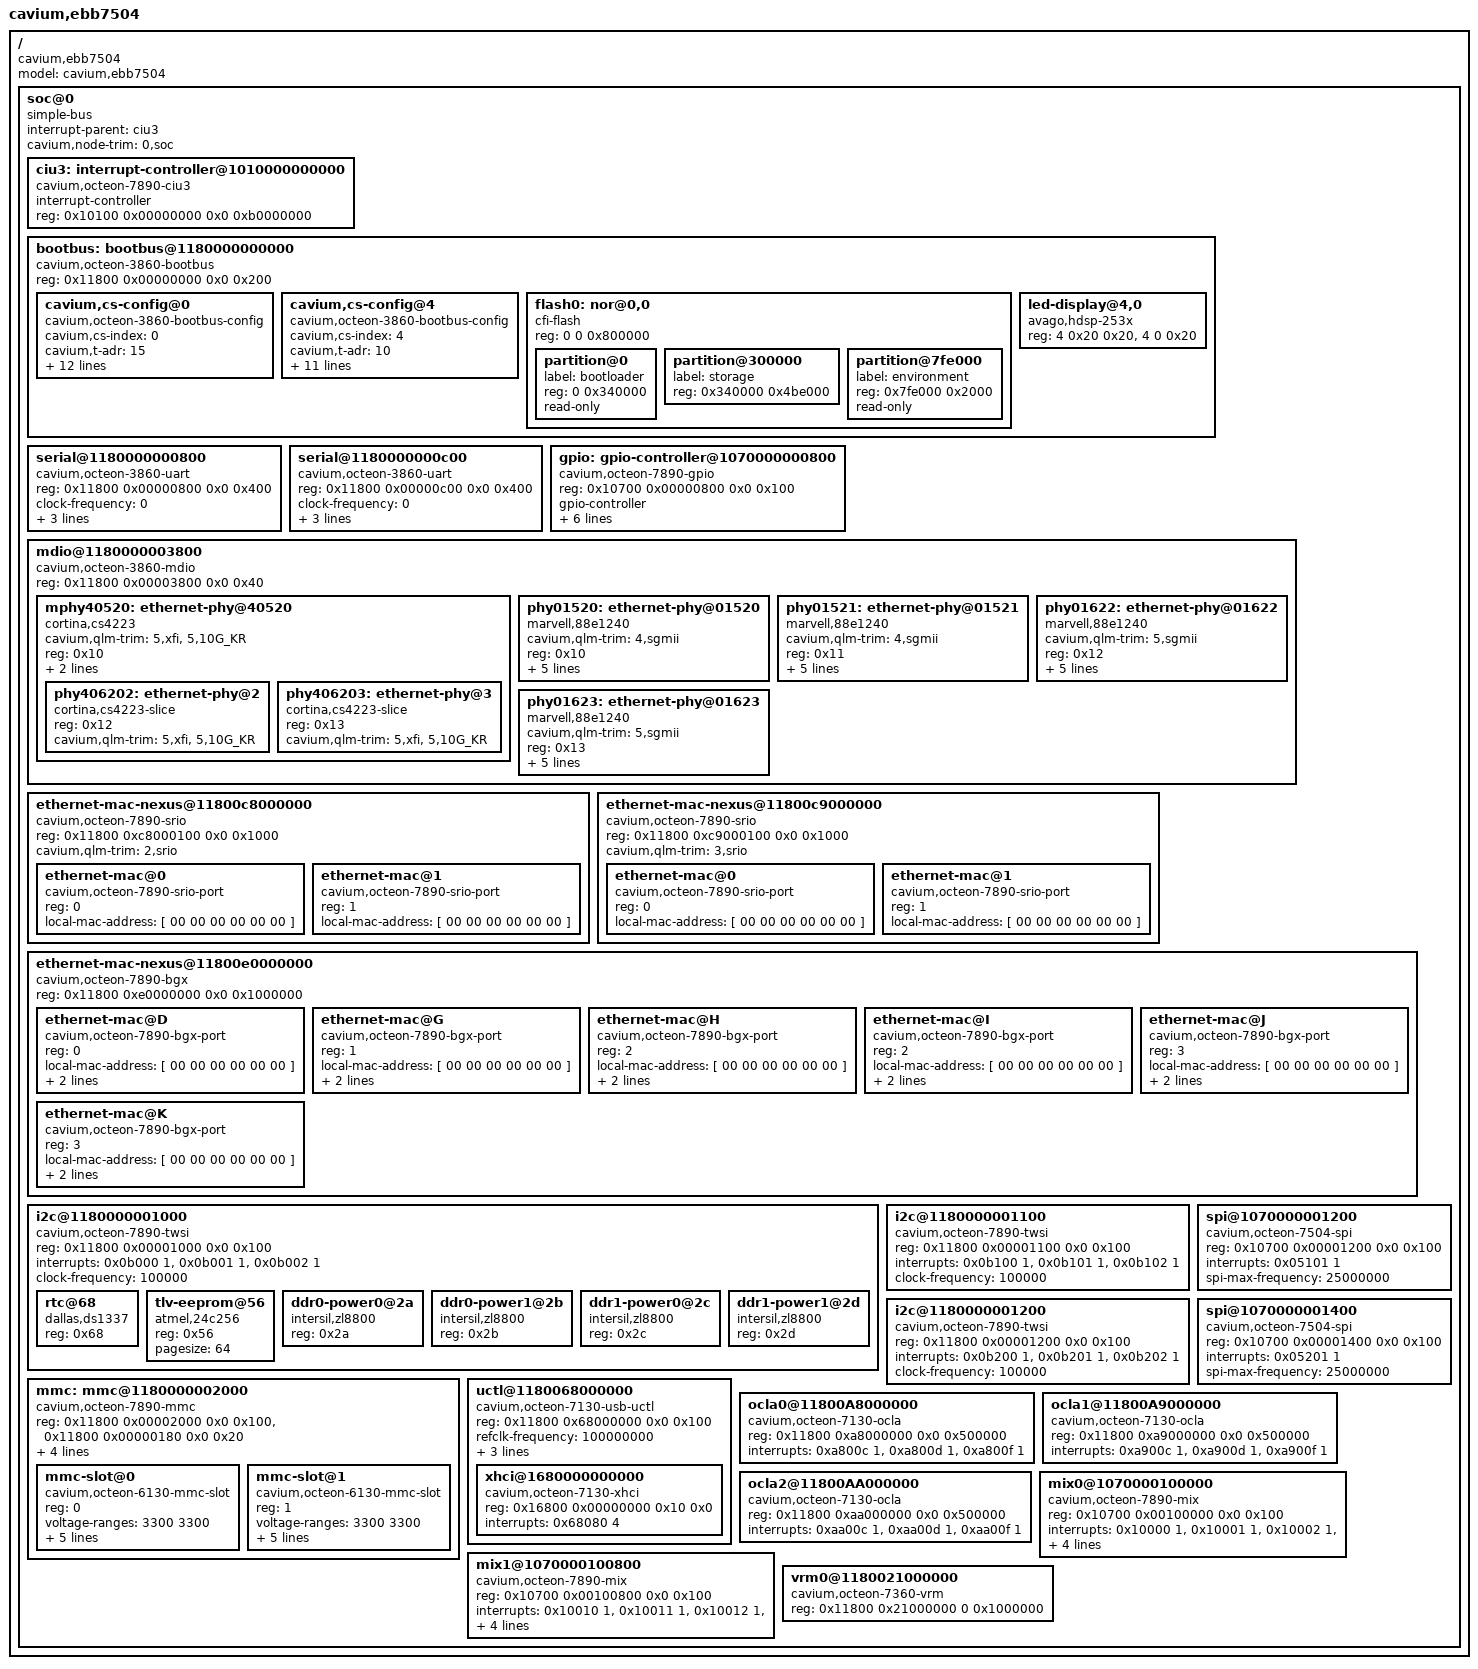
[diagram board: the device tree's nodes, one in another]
/dts-v1/;
/*
 * Cavium Inc. EVB CN7500
 */
/ {
	model = "cavium,ebb7504";
	compatible = "cavium,ebb7504";
	#address-cells = <2>;
	#size-cells = <2>;

	soc@0 {
		interrupt-parent = <&ciu3>;
		compatible = "simple-bus";
		#address-cells = <2>;
		#size-cells = <2>;
		ranges; /* Direct mapping */
		cavium,node-trim = "0,soc";

		ciu3: interrupt-controller@1010000000000 {
			compatible = "cavium,octeon-7890-ciu3";
			interrupt-controller;
			/* Interrupts are specified by two parts:
			 * 1) Source number (20 significant bits)
			 * 2) Trigger type: (4 == level, 1 == edge)
			 */
			#address-cells = <0>;
			#interrupt-cells = <2>;
			reg = <0x10100 0x00000000 0x0 0xb0000000>;
		};

		bootbus: bootbus@1180000000000 {
			compatible = "cavium,octeon-3860-bootbus";
			reg = <0x11800 0x00000000 0x0 0x200>;
			/* The chip select number and offset */
			#address-cells = <2>;
			/* The size of the chip select region */
			#size-cells = <1>;
			ranges = <0 0  0       0x1f400000  0xc00000>,
				 <1 0  0x10000 0x10000000  0>,
				 <2 0  0x10000 0x20000000  0>,
				 <3 0  0x10000 0x30000000  0>,
				 <4 0  0       0x1d020000  0x10000>,
				 <5 0  0x10000 0x50000000  0>,
				 <6 0  0x10000 0x60000000  0>,
				 <7 0  0x10000 0x70000000  0>;

			cavium,cs-config@0 {
				compatible = "cavium,octeon-3860-bootbus-config";
				cavium,cs-index = <0>;
				cavium,t-adr  = <15>;
				cavium,t-ce   = <55>;
				cavium,t-oe   = <55>;
				cavium,t-we   = <40>;
				cavium,t-rd-hld = <30>;
				cavium,t-wr-hld = <40>;
				cavium,t-pause  = <0>;
				cavium,t-wait   = <65>;
				cavium,t-page   = <35>;
				cavium,t-rd-dly = <0>;

				cavium,page-mode = <1>;
				cavium,pages     = <8>;
				cavium,bus-width = <8>;
			};
			cavium,cs-config@4 {
				compatible = "cavium,octeon-3860-bootbus-config";
				cavium,cs-index = <4>;
				cavium,t-adr  = <10>;
				cavium,t-ce   = <10>;
				cavium,t-oe   = <160>;
				cavium,t-we   = <100>;
				cavium,t-rd-hld = <10>;
				cavium,t-wr-hld = <0>;
				cavium,t-pause  = <50>;
				cavium,t-wait   = <60>;
				cavium,t-page   = <10>;
				cavium,t-rd-dly = <10>;

				cavium,pages     = <0>;
				cavium,bus-width = <8>;
			};
			flash0: nor@0,0 {
				compatible = "cfi-flash";
				reg = <0 0 0x800000>;
				#address-cells = <1>;
				#size-cells = <1>;

				partition@0 {
					label = "bootloader";
					reg = <0 0x340000>;
					read-only;
				};
				partition@300000 {
					label = "storage";
					reg = <0x340000 0x4be000>;
				};
				partition@7fe000 {
					label = "environment";
					reg = <0x7fe000 0x2000>;
					read-only;
				};
			};
			led-display@4,0 {
				compatible = "avago,hdsp-253x";
				reg = <4 0x20 0x20>, <4 0 0x20>;
			};
		};

		serial@1180000000800 {
			compatible = "cavium,octeon-3860-uart","ns16550";
			reg = <0x11800 0x00000800 0x0 0x400>;
			clock-frequency = <0>;
			current-speed = <115200>;
			reg-shift = <3>;
			interrupts = <0x08000 4>;
		};

		serial@1180000000c00 {
			compatible = "cavium,octeon-3860-uart","ns16550";
			reg = <0x11800 0x00000c00 0x0 0x400>;
			clock-frequency = <0>;
			current-speed = <115200>;
			reg-shift = <3>;
			interrupts = <0x08040 4>;
		};

		gpio: gpio-controller@1070000000800 {
			#gpio-cells = <2>;
			compatible = "cavium,octeon-7890-gpio";
			reg = <0x10700 0x00000800 0x0 0x100>;
			gpio-controller;
			/* Interrupts are specified by two parts:
			 * 1) GPIO pin number (0..15)
			 * 2) Triggering (1 - edge rising
			 *		  2 - edge falling
			 *		  4 - level active high
			 *		  8 - level active low)
			 */
			interrupt-controller;
			#interrupt-cells = <2>;
			/* The GPIO pins connect to 16 consecutive CUI bits */
			interrupts = <0x03000 4>, <0x03001 4>,
				     <0x03002 4>, <0x03003 4>,
				     <0x03004 4>, <0x03005 4>,
				     <0x03006 4>, <0x03007 4>,
				     <0x03008 4>, <0x03009 4>,
				     <0x0300a 4>, <0x0300b 4>,
				     <0x0300c 4>, <0x0300d 4>,
				     <0x0300e 4>, <0x0300f 4>;
		};

		/* SMI_0 -- The only bus connected on Rev 1 boards */
		mdio@1180000003800 {
			compatible = "cavium,octeon-3860-mdio";
			#address-cells = <1>;
			#size-cells = <0>;
			reg = <0x11800 0x00003800 0x0 0x40>;

			/**
			 * The phy names are broken down as follows:
			 * (m)phyxxyzzs
			 * where:
			 *	xx = 01 for SGMII, 10 for DXAUI, 20 for RXAUI
			 *	     and 40 for XFI/LXAUI
			 *	y = QLM/DLM number
			 *	zz = PHY address (decimal)
			 *	s = sub-phy number in the case of the Cortina
			 *	    PHY
			 * a mphy is a nexus phy that contains one or more
			 * sub-phys, for example the Cortina CS4223.
			 */

			/* DLM 4 */
			mphy40520: ethernet-phy@40520 {
				compatible = "cortina,cs4223", "ethernet-phy-nexus";
				cavium,qlm-trim = "5,xfi","5,10G_KR";
				reg = <0x10>;
				#address-cells = <1>;
				#size-cells = <0>;
				interrupt-parent = <&gpio>;
				interrupts = <5 8>;
				/* The Cortina CS4223 can be used either as
				 * XFI or 10G_KR.  In XFI, four separate ports
				 * are supported even though it's only a single
				 * PHY device.
				 */
				phy406202: ethernet-phy@2 {
					compatible = "cortina,cs4223-slice";
					reg = <0x12>;
					cavium,qlm-trim = "5,xfi","5,10G_KR";
				};
				phy406203: ethernet-phy@3 {
					compatible = "cortina,cs4223-slice";
					reg = <0x13>;
					cavium,qlm-trim = "5,xfi","5,10G_KR";
				};
			};
			phy01520: ethernet-phy@01520 {
				cavium,qlm-trim = "4,sgmii";
				reg = <0x10>;
				compatible = "marvell,88e1240", "ethernet-phy-ieee802.3-c22";
				interrupt-parent = <&gpio>;
				interrupts = <5 8>;

				marvell,reg-init = <3 0x10 0 0x8665>,
						   <3 0x11 0 0x00aa>,
						   <3 0x12 0 0x4105>,
						   <3 0x13 0 0x8a08>;
			};
			phy01521: ethernet-phy@01521 {
				cavium,qlm-trim = "4,sgmii";
				reg = <0x11>;
				compatible = "marvell,88e1240", "ethernet-phy-ieee802.3-c22";
				interrupt-parent = <&gpio>;
				interrupts = <5 8>; /* Pin 11, active low */

				marvell,reg-init = <3 0x10 0 0x8665>,
						   <3 0x11 0 0x00aa>,
						   <3 0x12 0 0x4105>,
						   <3 0x13 0 0x8a08>;
			};
			/* DLM 5 */
			phy01622: ethernet-phy@01622 {
				cavium,qlm-trim = "5,sgmii";
				reg = <0x12>;
				compatible = "marvell,88e1240", "ethernet-phy-ieee802.3-c22";
				interrupt-parent = <&gpio>;
				interrupts = <5 8>; /* Pin 11, active low */

				marvell,reg-init = <3 0x10 0 0x8665>,
						   <3 0x11 0 0x00aa>,
						   <3 0x12 0 0x4105>,
						   <3 0x13 0 0x8a08>;
			};
			phy01623: ethernet-phy@01623 {
				cavium,qlm-trim = "5,sgmii";
				reg = <0x13>;
				compatible = "marvell,88e1240", "ethernet-phy-ieee802.3-c22";
				interrupt-parent = <&gpio>;
				interrupts = <5 8>; /* Pin 11, active low */

				marvell,reg-init = <3 0x10 0 0x8665>,
						   <3 0x11 0 0x00aa>,
						   <3 0x12 0 0x4105>,
						   <3 0x13 0 0x8a08>;
			};
		};

		/* SRIO 0*/
		ethernet-mac-nexus@11800c8000000 {
			compatible = "cavium,octeon-7890-srio";
			reg = <0x11800 0xc8000100 0x0 0x1000>;
			#address-cells = <1>;
			#size-cells = <0>;
			cavium,qlm-trim = "2,srio";

			/* Port 0 */
			ethernet-mac@0 {
				compatible = "cavium,octeon-7890-srio-port";
				reg = <0>;
				local-mac-address = [ 00 00 00 00 00 00 ];
			};
			/* Port 1 */
			ethernet-mac@1 {
				compatible = "cavium,octeon-7890-srio-port";
				reg = <1>;
				local-mac-address = [ 00 00 00 00 00 00 ];
			};
		};

		/* SRIO 1*/
		ethernet-mac-nexus@11800c9000000 {
			compatible = "cavium,octeon-7890-srio";
			reg = <0x11800 0xc9000100 0x0 0x1000>;
			#address-cells = <1>;
			#size-cells = <0>;
			cavium,qlm-trim = "3,srio";

			/* Port 0 */
			ethernet-mac@0 {
				compatible = "cavium,octeon-7890-srio-port";
				reg = <0>;
				local-mac-address = [ 00 00 00 00 00 00 ];
			};
			/* Port 1 */
			ethernet-mac@1 {
				compatible = "cavium,octeon-7890-srio-port";
				reg = <1>;
				local-mac-address = [ 00 00 00 00 00 00 ];
			};
		};

		/* BGX definitions here must match sim_board.c settings. */
		/* BGX 0*/
		ethernet-mac-nexus@11800e0000000 {
			compatible = "cavium,octeon-7890-bgx";
			reg = <0x11800 0xe0000000 0x0 0x1000000>;
			#address-cells = <1>;
			#size-cells = <0>;

			/* SerDes 0, may differ from PCS Lane/LMAC */
			ethernet-mac@D {
				compatible = "cavium,octeon-7890-bgx-port";
				reg = <0>;
				local-mac-address = [ 00 00 00 00 00 00 ];
				phy-handle = <&phy01520>;
				cavium,qlm-trim = "4,sgmii";
			};
			/* SerDes 1, may differ from PCS Lane/LMAC */
			ethernet-mac@G {
				compatible = "cavium,octeon-7890-bgx-port";
				reg = <1>;
				local-mac-address = [ 00 00 00 00 00 00 ];
				phy-handle = <&phy01521>;
				cavium,qlm-trim = "4,sgmii";
			};
			/* SerDes 2 (XFI/10G_KR) */
			ethernet-mac@H {
				compatible = "cavium,octeon-7890-bgx-port";
				reg = <2>;
				local-mac-address = [ 00 00 00 00 00 00 ];
				phy-handle = <&phy406202>;
				cavium,qlm-trim = "5,xfi","5,10G_KR";
			};
			/* SerDes 2, may differ from PCS Lane/LMAC */
			ethernet-mac@I {
				compatible = "cavium,octeon-7890-bgx-port";
				reg = <2>;
				local-mac-address = [ 00 00 00 00 00 00 ];
				phy-handle = <&phy01622>;
				cavium,qlm-trim = "5,sgmii";
			};
			/* SerDes 3 (XFI/10G_KR) */
			ethernet-mac@J {
				compatible = "cavium,octeon-7890-bgx-port";
				reg = <3>;
				local-mac-address = [ 00 00 00 00 00 00 ];
				phy-handle = <&phy406203>;
				cavium,qlm-trim = "5,xfi","5,10G_KR";
			};
			/* SerDes 3, may differ from PCS Lane/LMAC */
			ethernet-mac@K {
				compatible = "cavium,octeon-7890-bgx-port";
				reg = <3>;
				local-mac-address = [ 00 00 00 00 00 00 ];
				phy-handle = <&phy01623>;
				cavium,qlm-trim = "5,sgmii";
			};
		};

		i2c@1180000001000 {
			#address-cells = <1>;
			#size-cells = <0>;
			compatible = "cavium,octeon-7890-twsi";
			reg = <0x11800 0x00001000 0x0 0x100>;
			/* INT_ST, INT_TS, INT_CORE */
			interrupts = <0x0b000 1>, <0x0b001 1>, <0x0b002 1>;
			clock-frequency = <100000>;

			rtc@68 {
				compatible = "dallas,ds1337";
				reg = <0x68>;
			};
			tlv-eeprom@56 {
				compatible = "atmel,24c256", "microchip,24lc256";
				reg = <0x56>;
				pagesize = <64>;
			};
			ddr0-power0@2a {
				compatible = "intersil,zl8800";
				reg = <0x2a>;
			};
			ddr0-power1@2b {
				compatible = "intersil,zl8800";
				reg = <0x2b>;
			};
			ddr1-power0@2c {
				compatible = "intersil,zl8800";
				reg = <0x2c>;
			};
			ddr1-power1@2d {
				compatible = "intersil,zl8800";
				reg = <0x2d>;
			};
		};

		i2c@1180000001100 {
			#address-cells = <1>;
			#size-cells = <0>;
			compatible = "cavium,octeon-7890-twsi";
			reg = <0x11800 0x00001100 0x0 0x100>;
			/* INT_ST, INT_TS, INT_CORE */
			interrupts = <0x0b100 1>, <0x0b101 1>, <0x0b102 1>;
			clock-frequency = <100000>;
		};

		i2c@1180000001200 {
			#address-cells = <1>;
			#size-cells = <0>;
			compatible = "cavium,octeon-7890-twsi";
			reg = <0x11800 0x00001200 0x0 0x100>;
			/* INT_ST, INT_TS, INT_CORE */
			interrupts = <0x0b200 1>, <0x0b201 1>, <0x0b202 1>;
			clock-frequency = <100000>;
		};

		mmc: mmc@1180000002000 {
			compatible = "cavium,octeon-7890-mmc",
				     "cavium,octeon-7360-mmc";
			reg = <0x11800 0x00002000 0x0 0x100>,
			      <0x11800 0x00000180 0x0 0x20>;
			#address-cells = <1>;
			#size-cells = <0>;
			/* EMM_INT_BUF_DONE,
			   EMM_INT_CMD_DONE,
			   EMM_INT_DMA_DONE,
			   EMM_INT_CMD_ERR,
			   EMM_INT_DMA_ERR,
			   EMM_INT_SWITCH_DONE,
			   EMM_INT_SWITCH_ERR,
			   EMM_DMA_DONE,
			   EMM_DMA_FIFO*/
			interrupts = <0x09040 1>,
				     <0x09041 1>,
				     <0x09042 1>,
				     <0x09043 1>,
				     <0x09044 1>,
				     <0x09045 1>,
				     <0x09046 1>,
				     <0x09000 1>,
				     <0x09001 1>;

			/* Power on GPIO 8, active high */
			power-gpios = <&gpio 8 0>;

			/* The board has two MMC slots
			 * If both are occupied, the speed must be reduced,
			 * as extra data-line load increases slew time,
			 * and dat-skew adjustment does not help significantly.
			 */
			mmc-slot@0 {
				compatible = "cavium,octeon-6130-mmc-slot";
				reg = <0>;
				voltage-ranges = <3300 3300>;
				//spi-max-frequency = <52000000>; // just one
				spi-max-frequency = <37000000>; // both slots
				/* bus width can be 1, 4 or 8 */
				bus-width = <8>; /* new std property */
				cavium,bus-max-width = <8>; /* custom property */
				wp-gpios = <&gpio 22 0>; /* active high */
				cd-gpios = <&gpio 23 1>; /* active low */
			};
			mmc-slot@1 {
				compatible = "cavium,octeon-6130-mmc-slot";
				reg = <1>;
				voltage-ranges = <3300 3300>;
				//spi-max-frequency = <52000000>; // just one
				spi-max-frequency = <37000000>; // both slots
				/* bus width can be 1, 4 or 8 */
				bus-width = <8>; /* new std property */
				cavium,bus-max-width = <8>; /* custom property */
				wp-gpios = <&gpio 24 0>; /* active high */
				cd-gpios = <&gpio 25 1>; /* active low */
			};
		};

		spi@1070000001200 {
			compatible = "cavium,octeon-7504-spi", "cavium,octeon-3010-spi";
			reg = <0x10700 0x00001200 0x0 0x100>;
			interrupts = <0x05101 1>;
			#address-cells = <1>;
			#size-cells = <0>;
			spi-max-frequency = <25000000>;
		};

		spi@1070000001400 {
			compatible = "cavium,octeon-7504-spi", "cavium,octeon-3010-spi";
			reg = <0x10700 0x00001400 0x0 0x100>;
			interrupts = <0x05201 1>;
			#address-cells = <1>;
			#size-cells = <0>;
			spi-max-frequency = <25000000>;
		};

		/* USB 0 */
		uctl@1180068000000 {
			compatible = "cavium,octeon-7130-usb-uctl";
			reg = <0x11800 0x68000000 0x0 0x100>;
			ranges; /* Direct mapping */
			#address-cells = <2>;
			#size-cells = <2>;
			/* Only 100MHz allowed */
			refclk-frequency = <100000000>;
			/* Only "dlmc_ref_clk0" is supported for 75xx */
			refclk-type-ss = "dlmc_ref_clk0";
			/* Only "dlmc_ref_clk0" is supported for 75xx */
			refclk-type-hs = "dlmc_ref_clk0";

			/* Power is specified by three parts:
			 * 1) GPIO handle (must be &gpio)
			 * 2) GPIO pin number
			 * 3) Active high (0) or active low (1)
			 */
			power = <&gpio 20 0>;

			xhci@1680000000000 {
				compatible = "cavium,octeon-7130-xhci","synopsys,dwc3";
				reg = <0x16800 0x00000000 0x10 0x0>;
				interrupts = <0x68080 4>; /* UAHC_IMAN, level */
			};
		};

		ocla0@11800A8000000 {
			compatible = "cavium,octeon-7130-ocla";
			reg = <0x11800 0xa8000000 0x0 0x500000>;
			interrupts = <0xa800c 1>, /* Fsm0 */
				     <0xa800d 1>, /* Fsm1 */
				     <0xa800f 1>; /* Trigfull */
		};

		ocla1@11800A9000000 {
			compatible = "cavium,octeon-7130-ocla";
			reg = <0x11800 0xa9000000 0x0 0x500000>;
			interrupts = <0xa900c 1>, /* Fsm0 */
				     <0xa900d 1>, /* Fsm1 */
				     <0xa900f 1>; /* Trigfull */
		};

		ocla2@11800AA000000 {
			compatible = "cavium,octeon-7130-ocla";
			reg = <0x11800 0xaa000000 0x0 0x500000>;
			interrupts = <0xaa00c 1>, /* Fsm0 */
				     <0xaa00d 1>, /* Fsm1 */
				     <0xaa00f 1>; /* Trigfull */
		};

		mix0@1070000100000 {
			compatible = "cavium,octeon-7890-mix";
			reg = <0x10700 0x00100000 0x0 0x100>;
			interrupts = <0x10000 1>, /* ODBLOVF */
				     <0x10001 1>, /* IDBLOVF */
				     <0x10002 1>, /* ORTHRESH */
				     <0x10003 1>, /* IRTHRESH */
				     <0x10004 1>, /* DATA_DRP */
				     <0x10005 1>, /* IRUN */
				     <0x10006 1>, /* ORUN */
				     <0x10007 1>; /* TS */
			local-mac-address = [ 00 00 00 00 00 00 ];
			cavium,mac-handle = <0xffff>;
		};
		mix1@1070000100800 {
			compatible = "cavium,octeon-7890-mix";
			reg = <0x10700 0x00100800 0x0 0x100>;
			interrupts = <0x10010 1>, /* ODBLOVF */
				     <0x10011 1>, /* IDBLOVF */
				     <0x10012 1>, /* ORTHRESH */
				     <0x10013 1>, /* IRTHRESH */
				     <0x10014 1>, /* DATA_DRP */
				     <0x10015 1>, /* IRUN */
				     <0x10016 1>, /* ORUN */
				     <0x10017 1>; /* TS */
			local-mac-address = [ 00 00 00 00 00 00 ];
			cavium,mac-handle = <0xffff>;
		};

		vrm0@1180021000000 {
			compatible = "cavium,octeon-7360-vrm";
			reg = <0x11800 0x21000000 0 0x1000000>;
		};
	};
 };

